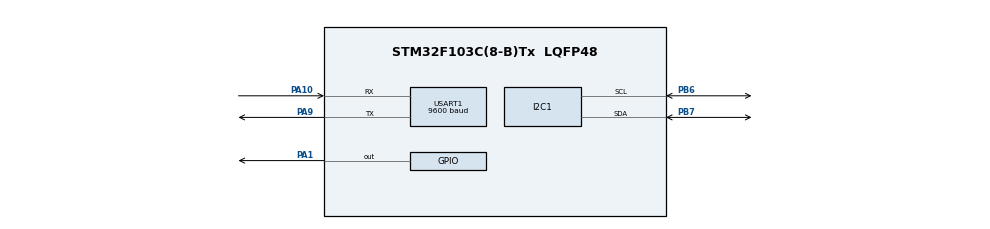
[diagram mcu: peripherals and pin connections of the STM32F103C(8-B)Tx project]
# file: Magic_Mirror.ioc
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I2C1.I2C_Mode=I2C_Fast
Mcu.Family=STM32F1
Mcu.Name=STM32F103C(8-B)Tx
Mcu.Package=LQFP48
NVIC.PriorityGroup=NVIC_PRIORITYGROUP_4
PA1.Signal=GPIO_Output
PA10.Mode=Asynchronous
PA10.Signal=USART1_RX
PA9.Mode=Asynchronous
PA9.Signal=USART1_TX
PB6.Mode=I2C
PB6.Signal=I2C1_SCL
PB7.Mode=I2C
PB7.Signal=I2C1_SDA
ProjectManager.HeapSize=0x200
ProjectManager.StackSize=0x400
ProjectManager.TargetToolchain=TrueSTUDIO
RCC.APB1Freq_Value=8000000
RCC.APB2Freq_Value=8000000
USART1.BaudRate=9600
USART1.VirtualMode=VM_ASYNC
VP_SYS_VS_ND.Mode=No_Debug
board=custom

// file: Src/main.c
/* USER CODE BEGIN Header */
/**
  ******************************************************************************
  * @file           : main.c
  * @brief          : Main program body
  ******************************************************************************
  * @attention
  *
  * <h2><center>&copy; Copyright (c) 2019 STMicroelectronics.
  * All rights reserved.</center></h2>
  *
  * This software component is licensed by ST under BSD 3-Clause license,
  * the "License"; You may not use this file except in compliance with the
  * License. You may obtain a copy of the License at:
  *                        opensource.org/licenses/BSD-3-Clause
  *
  ******************************************************************************
  */
/* USER CODE END Header */

#include "main.h"
#include "i2c.h"
#include "usart.h"
#include "gpio.h"
#include "bluetooth_controller.h"
#include "display.h"
#include "ssd1306.h"
#include "fonts.h"

void SystemClock_Config(void);

int main(void)
{

  /* MCU Configuration--------------------------------------------------------*/

  /* Reset of all peripherals, Initializes the Flash interface and the Systick. */
  HAL_Init();

  /* Configure the system clock */
  SystemClock_Config();

  /* Initialize all configured peripherals */
  MX_GPIO_Init();
  MX_USART1_UART_Init();
  MX_I2C1_Init();
  SSD1306_Init();
  perform_demo();

  /* USER CODE BEGIN WHILE */
  while (1)
  {
    toggle_led_light_off();
    toggle_led_light_on();
    /* USER CODE END WHILE */

  }
}

void SystemClock_Config(void)
{
  RCC_OscInitTypeDef RCC_OscInitStruct = {0};
  RCC_ClkInitTypeDef RCC_ClkInitStruct = {0};

  /** Initializes the CPU, AHB and APB busses clocks
  */
  RCC_OscInitStruct.OscillatorType = RCC_OSCILLATORTYPE_HSI;
  RCC_OscInitStruct.HSIState = RCC_HSI_ON;
  RCC_OscInitStruct.HSICalibrationValue = RCC_HSICALIBRATION_DEFAULT;
  RCC_OscInitStruct.PLL.PLLState = RCC_PLL_NONE;
  if (HAL_RCC_OscConfig(&RCC_OscInitStruct) != HAL_OK)
  {
    Error_Handler();
  }
  /** Initializes the CPU, AHB and APB busses clocks
  */
  RCC_ClkInitStruct.ClockType = RCC_CLOCKTYPE_HCLK | RCC_CLOCKTYPE_SYSCLK | RCC_CLOCKTYPE_PCLK1 | RCC_CLOCKTYPE_PCLK2;
  RCC_ClkInitStruct.SYSCLKSource = RCC_SYSCLKSOURCE_HSI;
  RCC_ClkInitStruct.AHBCLKDivider = RCC_SYSCLK_DIV1;
  RCC_ClkInitStruct.APB1CLKDivider = RCC_HCLK_DIV1;
  RCC_ClkInitStruct.APB2CLKDivider = RCC_HCLK_DIV1;

  if (HAL_RCC_ClockConfig(&RCC_ClkInitStruct, FLASH_LATENCY_0) != HAL_OK)
  {
    Error_Handler();
  }
}

void Error_Handler(void)
{
}

/************************ (C) COPYRIGHT STMicroelectronics *****END OF FILE****/
